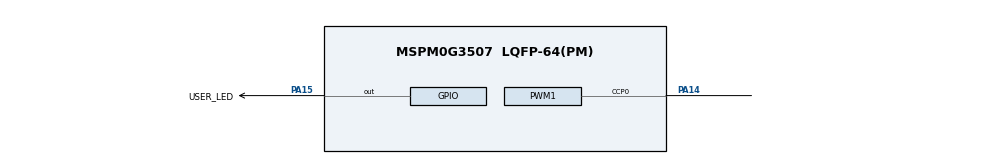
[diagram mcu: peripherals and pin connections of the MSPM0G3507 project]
/**
 * These arguments were used when this file was generated. They will be automatically applied on subsequent loads
 * via the GUI or CLI. Run CLI with '--help' for additional information on how to override these arguments.
 * @cliArgs --device "MSPM0G350X" --part "Default" --package "LQFP-64(PM)" --product "mspm0_sdk@2.10.00.04"
 * @v2CliArgs --device "MSPM0G3507" --package "LQFP-64(PM)" --product "mspm0_sdk@2.10.00.04"
 * @versions {"tool":"1.27.1+4634"}
 */

/**
 * Import the modules used in this configuration.
 */
const GPIO    = scripting.addModule("/ti/driverlib/GPIO", {}, false);
const GPIO1   = GPIO.addInstance();
const PWM     = scripting.addModule("/ti/driverlib/PWM", {}, false);
const PWM1    = PWM.addInstance();
const SYSCTL  = scripting.addModule("/ti/driverlib/SYSCTL");
const SYSTICK = scripting.addModule("/ti/driverlib/SYSTICK");

/**
 * Write custom configuration values to the imported modules.
 */
GPIO1.$name                         = "GPIO_LEDS";
GPIO1.port                          = "PORTA";
GPIO1.associatedPins[0].$name       = "USER_LED";
GPIO1.associatedPins[0].assignedPin = "15";
GPIO1.associatedPins[0].pin.$assign = "PA15";

const Board = scripting.addModule("/ti/driverlib/Board", {}, false);

PWM1.$name                      = "PWM_0";
PWM1.clockDivider               = 8;
PWM1.pwmMode                    = "EDGE_ALIGN_UP";
PWM1.ccIndex                    = [0];
PWM1.timerCount                 = 4000;
PWM1.PWM_CHANNEL_0.$name        = "ti_driverlib_pwm_PWMTimerCC0";
PWM1.PWM_CHANNEL_0.dutyCycle    = 50;
PWM1.ccp0PinConfig.$name        = "ti_driverlib_gpio_GPIOPinGeneric0";
PWM1.peripheral.$assign         = "TIMG12";
PWM1.peripheral.ccp0Pin.$assign = "PA14";

SYSCTL.forceDefaultClkConfig = true;
SYSCTL.clockTreeEn           = true;

SYSTICK.periodEnable    = true;
SYSTICK.period          = 32000;
SYSTICK.interruptEnable = true;

/**
 * Pinmux solution for unlocked pins/peripherals. This ensures that minor changes to the automatic solver in a future
 * version of the tool will not impact the pinmux you originally saw.  These lines can be completely deleted in order to
 * re-solve from scratch.
 */
Board.peripheral.$suggestSolution          = "DEBUGSS";
Board.peripheral.swclkPin.$suggestSolution = "PA20";
Board.peripheral.swdioPin.$suggestSolution = "PA19";
